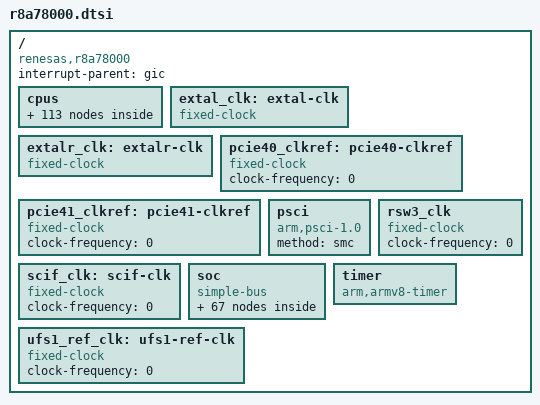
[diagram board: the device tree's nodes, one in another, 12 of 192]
// SPDX-License-Identifier: (GPL-2.0-only OR BSD-2-Clause)
/*
 * Device Tree Source for the R-Car X5H (R8A78000) SoC
 *
 * Copyright (C) 2025 Renesas Electronics Corp.
 */

#include <dt-bindings/clock/renesas,r8a78000-cpg.h>
#include <dt-bindings/power/renesas,r8a78000-mdlc.h>
#include <dt-bindings/interrupt-controller/arm-gic.h>

/ {
	compatible = "renesas,r8a78000";
	#address-cells = <2>;
	#size-cells = <2>;
	interrupt-parent = <&gic>;

	cpus {
		#address-cells = <2>;
		#size-cells = <0>;

		cpu-map {
			cluster0 {
				core0 {
					cpu = <&a720_0>;
				};
				core1 {
					cpu = <&a720_1>;
				};
				core2 {
					cpu = <&a720_2>;
				};
				core3 {
					cpu = <&a720_3>;
				};
			};

			cluster1 {
				core0 {
					cpu = <&a720_4>;
				};
				core1 {
					cpu = <&a720_5>;
				};
				core2 {
					cpu = <&a720_6>;
				};
				core3 {
					cpu = <&a720_7>;
				};
			};

			cluster2 {
				core0 {
					cpu = <&a720_8>;
				};
				core1 {
					cpu = <&a720_9>;
				};
				core2 {
					cpu = <&a720_10>;
				};
				core3 {
					cpu = <&a720_11>;
				};
			};

			cluster3 {
				core0 {
					cpu = <&a720_12>;
				};
				core1 {
					cpu = <&a720_13>;
				};
				core2 {
					cpu = <&a720_14>;
				};
				core3 {
					cpu = <&a720_15>;
				};
			};

			cluster4 {
				core0 {
					cpu = <&a720_16>;
				};
				core1 {
					cpu = <&a720_17>;
				};
				core2 {
					cpu = <&a720_18>;
				};
				core3 {
					cpu = <&a720_19>;
				};
			};

			cluster5 {
				core0 {
					cpu = <&a720_20>;
				};
				core1 {
					cpu = <&a720_21>;
				};
				core2 {
					cpu = <&a720_22>;
				};
				core3 {
					cpu = <&a720_23>;
				};
			};

			cluster6 {
				core0 {
					cpu = <&a720_24>;
				};
				core1 {
					cpu = <&a720_25>;
				};
				core2 {
					cpu = <&a720_26>;
				};
				core3 {
					cpu = <&a720_27>;
				};
			};

			cluster7 {
				core0 {
					cpu = <&a720_28>;
				};
				core1 {
					cpu = <&a720_29>;
				};
				core2 {
					cpu = <&a720_30>;
				};
				core3 {
					cpu = <&a720_31>;
				};
			};
		};

		a720_0: cpu@0 {
			compatible = "arm,cortex-a720ae";
			reg = <0x0 0x0>;
			device_type = "cpu";
			enable-method = "psci";
			next-level-cache = <&L2_CA720_0>;
		};

		a720_1: cpu@100 {
			compatible = "arm,cortex-a720ae";
			reg = <0x0 0x100>;
			device_type = "cpu";
			enable-method = "psci";
			next-level-cache = <&L2_CA720_1>;
		};

		a720_2: cpu@200 {
			compatible = "arm,cortex-a720ae";
			reg = <0x0 0x200>;
			device_type = "cpu";
			enable-method = "psci";
			next-level-cache = <&L2_CA720_2>;
		};

		a720_3: cpu@300 {
			compatible = "arm,cortex-a720ae";
			reg = <0x0 0x300>;
			device_type = "cpu";
			enable-method = "psci";
			next-level-cache = <&L2_CA720_3>;
		};

		a720_4: cpu@10000 {
			compatible = "arm,cortex-a720ae";
			reg = <0x0 0x10000>;
			device_type = "cpu";
			enable-method = "psci";
			next-level-cache = <&L2_CA720_4>;
		};

		a720_5: cpu@10100 {
			compatible = "arm,cortex-a720ae";
			reg = <0x0 0x10100>;
			device_type = "cpu";
			enable-method = "psci";
			next-level-cache = <&L2_CA720_5>;
		};

		a720_6: cpu@10200 {
			compatible = "arm,cortex-a720ae";
			reg = <0x0 0x10200>;
			device_type = "cpu";
			enable-method = "psci";
			next-level-cache = <&L2_CA720_6>;
		};

		a720_7: cpu@10300 {
			compatible = "arm,cortex-a720ae";
			reg = <0x0 0x10300>;
			device_type = "cpu";
			enable-method = "psci";
			next-level-cache = <&L2_CA720_7>;
		};

		a720_8: cpu@20000 {
			compatible = "arm,cortex-a720ae";
			reg = <0x0 0x20000>;
			device_type = "cpu";
			enable-method = "psci";
			next-level-cache = <&L2_CA720_8>;
		};

		a720_9: cpu@20100 {
			compatible = "arm,cortex-a720ae";
			reg = <0x0 0x20100>;
			device_type = "cpu";
			enable-method = "psci";
			next-level-cache = <&L2_CA720_9>;
		};

		a720_10: cpu@20200 {
			compatible = "arm,cortex-a720ae";
			reg = <0x0 0x20200>;
			device_type = "cpu";
			enable-method = "psci";
			next-level-cache = <&L2_CA720_10>;
		};

		a720_11: cpu@20300 {
			compatible = "arm,cortex-a720ae";
			reg = <0x0 0x20300>;
			device_type = "cpu";
			enable-method = "psci";
			next-level-cache = <&L2_CA720_11>;
		};

		a720_12: cpu@30000 {
			compatible = "arm,cortex-a720ae";
			reg = <0x0 0x30000>;
			device_type = "cpu";
			enable-method = "psci";
			next-level-cache = <&L2_CA720_12>;
		};

		a720_13: cpu@30100 {
			compatible = "arm,cortex-a720ae";
			reg = <0x0 0x30100>;
			device_type = "cpu";
			enable-method = "psci";
			next-level-cache = <&L2_CA720_13>;
		};

		a720_14: cpu@30200 {
			compatible = "arm,cortex-a720ae";
			reg = <0x0 0x30200>;
			device_type = "cpu";
			enable-method = "psci";
			next-level-cache = <&L2_CA720_14>;
		};

		a720_15: cpu@30300 {
			compatible = "arm,cortex-a720ae";
			reg = <0x0 0x30300>;
			device_type = "cpu";
			enable-method = "psci";
			next-level-cache = <&L2_CA720_15>;
		};

		a720_16: cpu@40000 {
			compatible = "arm,cortex-a720ae";
			reg = <0x0 0x40000>;
			device_type = "cpu";
			enable-method = "psci";
			next-level-cache = <&L2_CA720_16>;
		};

		a720_17: cpu@40100 {
			compatible = "arm,cortex-a720ae";
			reg = <0x0 0x40100>;
			device_type = "cpu";
			enable-method = "psci";
			next-level-cache = <&L2_CA720_17>;
		};

		a720_18: cpu@40200 {
			compatible = "arm,cortex-a720ae";
			reg = <0x0 0x40200>;
			device_type = "cpu";
			enable-method = "psci";
			next-level-cache = <&L2_CA720_18>;
		};

		a720_19: cpu@40300 {
			compatible = "arm,cortex-a720ae";
			reg = <0x0 0x40300>;
			device_type = "cpu";
			enable-method = "psci";
			next-level-cache = <&L2_CA720_19>;
		};

		a720_20: cpu@50000 {
			compatible = "arm,cortex-a720ae";
			reg = <0x0 0x50000>;
			device_type = "cpu";
			enable-method = "psci";
			next-level-cache = <&L2_CA720_20>;
		};

		a720_21: cpu@50100 {
			compatible = "arm,cortex-a720ae";
			reg = <0x0 0x50100>;
			device_type = "cpu";
			enable-method = "psci";
			next-level-cache = <&L2_CA720_21>;
		};

		a720_22: cpu@50200 {
			compatible = "arm,cortex-a720ae";
			reg = <0x0 0x50200>;
			device_type = "cpu";
			enable-method = "psci";
			next-level-cache = <&L2_CA720_22>;
		};

		a720_23: cpu@50300 {
			compatible = "arm,cortex-a720ae";
			reg = <0x0 0x50300>;
			device_type = "cpu";
			enable-method = "psci";
			next-level-cache = <&L2_CA720_23>;
		};

		a720_24: cpu@60000 {
			compatible = "arm,cortex-a720ae";
			reg = <0x0 0x60000>;
			device_type = "cpu";
			enable-method = "psci";
			next-level-cache = <&L2_CA720_24>;
		};

		a720_25: cpu@60100 {
			compatible = "arm,cortex-a720ae";
			reg = <0x0 0x60100>;
			device_type = "cpu";
			enable-method = "psci";
			next-level-cache = <&L2_CA720_25>;
		};

		a720_26: cpu@60200 {
			compatible = "arm,cortex-a720ae";
			reg = <0x0 0x60200>;
			device_type = "cpu";
			enable-method = "psci";
			next-level-cache = <&L2_CA720_26>;
		};

		a720_27: cpu@60300 {
			compatible = "arm,cortex-a720ae";
			reg = <0x0 0x60300>;
			device_type = "cpu";
			enable-method = "psci";
			next-level-cache = <&L2_CA720_27>;
		};

		a720_28: cpu@70000 {
			compatible = "arm,cortex-a720ae";
			reg = <0x0 0x70000>;
			device_type = "cpu";
			enable-method = "psci";
			next-level-cache = <&L2_CA720_28>;
		};

		a720_29: cpu@70100 {
			compatible = "arm,cortex-a720ae";
			reg = <0x0 0x70100>;
			device_type = "cpu";
			enable-method = "psci";
			next-level-cache = <&L2_CA720_29>;
		};

		a720_30: cpu@70200 {
			compatible = "arm,cortex-a720ae";
			reg = <0x0 0x70200>;
			device_type = "cpu";
			enable-method = "psci";
			next-level-cache = <&L2_CA720_30>;
		};

		a720_31: cpu@70300 {
			compatible = "arm,cortex-a720ae";
			reg = <0x0 0x70300>;
			device_type = "cpu";
			enable-method = "psci";
			next-level-cache = <&L2_CA720_31>;
		};

		L2_CA720_0: cache-controller-200 {
			compatible = "cache";
			cache-unified;
			cache-level = <2>;
			next-level-cache = <&L3_CA720_0>;
		};

		L2_CA720_1: cache-controller-201 {
			compatible = "cache";
			cache-unified;
			cache-level = <2>;
			next-level-cache = <&L3_CA720_0>;
		};

		L2_CA720_2: cache-controller-202 {
			compatible = "cache";
			cache-unified;
			cache-level = <2>;
			next-level-cache = <&L3_CA720_0>;
		};

		L2_CA720_3: cache-controller-203 {
			compatible = "cache";
			cache-unified;
			cache-level = <2>;
			next-level-cache = <&L3_CA720_0>;
		};

		L2_CA720_4: cache-controller-204 {
			compatible = "cache";
			cache-unified;
			cache-level = <2>;
			next-level-cache = <&L3_CA720_1>;
		};

		L2_CA720_5: cache-controller-205 {
			compatible = "cache";
			cache-unified;
			cache-level = <2>;
			next-level-cache = <&L3_CA720_1>;
		};

		L2_CA720_6: cache-controller-206 {
			compatible = "cache";
			cache-unified;
			cache-level = <2>;
			next-level-cache = <&L3_CA720_1>;
		};

		L2_CA720_7: cache-controller-207 {
			compatible = "cache";
			cache-unified;
			cache-level = <2>;
			next-level-cache = <&L3_CA720_1>;
		};

		L2_CA720_8: cache-controller-208 {
			compatible = "cache";
			cache-unified;
			cache-level = <2>;
			next-level-cache = <&L3_CA720_2>;
		};

		L2_CA720_9: cache-controller-209 {
			compatible = "cache";
			cache-unified;
			cache-level = <2>;
			next-level-cache = <&L3_CA720_2>;
		};

		L2_CA720_10: cache-controller-210 {
			compatible = "cache";
			cache-unified;
			cache-level = <2>;
			next-level-cache = <&L3_CA720_2>;
		};

		L2_CA720_11: cache-controller-211 {
			compatible = "cache";
			cache-unified;
			cache-level = <2>;
			next-level-cache = <&L3_CA720_2>;
		};

		L2_CA720_12: cache-controller-212 {
			compatible = "cache";
			cache-unified;
			cache-level = <2>;
			next-level-cache = <&L3_CA720_3>;
		};

		L2_CA720_13: cache-controller-213 {
			compatible = "cache";
			cache-unified;
			cache-level = <2>;
			next-level-cache = <&L3_CA720_3>;
		};

		L2_CA720_14: cache-controller-214 {
			compatible = "cache";
			cache-unified;
			cache-level = <2>;
			next-level-cache = <&L3_CA720_3>;
		};

		L2_CA720_15: cache-controller-215 {
			compatible = "cache";
			cache-unified;
			cache-level = <2>;
			next-level-cache = <&L3_CA720_3>;
		};

		L2_CA720_16: cache-controller-216 {
			compatible = "cache";
			cache-unified;
			cache-level = <2>;
			next-level-cache = <&L3_CA720_4>;
		};

		L2_CA720_17: cache-controller-217 {
			compatible = "cache";
			cache-unified;
			cache-level = <2>;
			next-level-cache = <&L3_CA720_4>;
		};

		L2_CA720_18: cache-controller-218 {
			compatible = "cache";
			cache-unified;
			cache-level = <2>;
			next-level-cache = <&L3_CA720_4>;
		};

		L2_CA720_19: cache-controller-219 {
			compatible = "cache";
			cache-unified;
			cache-level = <2>;
			next-level-cache = <&L3_CA720_4>;
		};

		L2_CA720_20: cache-controller-220 {
			compatible = "cache";
			cache-unified;
			cache-level = <2>;
			next-level-cache = <&L3_CA720_5>;
		};

		L2_CA720_21: cache-controller-221 {
			compatible = "cache";
			cache-unified;
			cache-level = <2>;
			next-level-cache = <&L3_CA720_5>;
		};

		L2_CA720_22: cache-controller-222 {
			compatible = "cache";
			cache-unified;
			cache-level = <2>;
			next-level-cache = <&L3_CA720_5>;
		};

		L2_CA720_23: cache-controller-223 {
			compatible = "cache";
			cache-unified;
			cache-level = <2>;
			next-level-cache = <&L3_CA720_5>;
		};

		L2_CA720_24: cache-controller-224 {
			compatible = "cache";
			cache-unified;
			cache-level = <2>;
			next-level-cache = <&L3_CA720_6>;
		};

		L2_CA720_25: cache-controller-225 {
			compatible = "cache";
			cache-unified;
			cache-level = <2>;
			next-level-cache = <&L3_CA720_6>;
		};

		L2_CA720_26: cache-controller-226 {
			compatible = "cache";
			cache-unified;
			cache-level = <2>;
			next-level-cache = <&L3_CA720_6>;
		};

		L2_CA720_27: cache-controller-227 {
			compatible = "cache";
			cache-unified;
			cache-level = <2>;
			next-level-cache = <&L3_CA720_6>;
		};

		L2_CA720_28: cache-controller-228 {
			compatible = "cache";
			cache-unified;
			cache-level = <2>;
			next-level-cache = <&L3_CA720_7>;
		};

		L2_CA720_29: cache-controller-229 {
			compatible = "cache";
			cache-unified;
			cache-level = <2>;
			next-level-cache = <&L3_CA720_7>;
		};

		L2_CA720_30: cache-controller-230 {
			compatible = "cache";
			cache-unified;
			cache-level = <2>;
			next-level-cache = <&L3_CA720_7>;
		};

		L2_CA720_31: cache-controller-231 {
			compatible = "cache";
			cache-unified;
			cache-level = <2>;
			next-level-cache = <&L3_CA720_7>;
		};

		L3_CA720_0: cache-controller-30 {
			compatible = "cache";
			cache-unified;
			cache-level = <3>;
		};

		L3_CA720_1: cache-controller-31 {
			compatible = "cache";
			cache-unified;
			cache-level = <3>;
		};

		L3_CA720_2: cache-controller-32 {
			compatible = "cache";
			cache-unified;
			cache-level = <3>;
		};

		L3_CA720_3: cache-controller-33 {
			compatible = "cache";
			cache-unified;
			cache-level = <3>;
		};

		L3_CA720_4: cache-controller-34 {
			compatible = "cache";
			cache-unified;
			cache-level = <3>;
		};

		L3_CA720_5: cache-controller-35 {
			compatible = "cache";
			cache-unified;
			cache-level = <3>;
		};

		L3_CA720_6: cache-controller-36 {
			compatible = "cache";
			cache-unified;
			cache-level = <3>;
		};

		L3_CA720_7: cache-controller-37 {
			compatible = "cache";
			cache-unified;
			cache-level = <3>;
		};
	};

	extal_clk: extal-clk {
		compatible = "fixed-clock";
		#clock-cells = <0>;
		/* clock-frequency must be set on board */
	};

	extalr_clk: extalr-clk {
		compatible = "fixed-clock";
		#clock-cells = <0>;
		/* clock-frequency must be set on board */
	};

	pcie40_clkref: pcie40-clkref {
		compatible = "fixed-clock";
		#clock-cells = <0>;
		/* This value must be overridden by the board */
		clock-frequency = <0>;
	};

	pcie41_clkref: pcie41-clkref {
		compatible = "fixed-clock";
		#clock-cells = <0>;
		/* This value must be overridden by the board */
		clock-frequency = <0>;
	};

	psci {
		compatible = "arm,psci-1.0";
		method = "smc";
	};

	rsw3_clk: rsw3_clk {
		compatible = "fixed-clock";
		#clock-cells = <0>;
		clock-frequency = <0>;
	};

	/* External SCIF clock - to be overridden by boards that provide it */
	scif_clk: scif-clk {
		compatible = "fixed-clock";
		#clock-cells = <0>;
		clock-frequency = <0>; /* optional */
	};

	soc: soc {
		compatible = "simple-bus";
		#address-cells = <2>;
		#size-cells = <2>;
		ranges;

		mfis: system-controller@189e0000 {
			compatible = "renesas,r8a78000-mfis";
			reg = <0 0x189e0000 0 0x1000>, <0 0x18800000 0 0x40000>;
			reg-names = "common", "mboxes";
			interrupts = <GIC_SPI 101 IRQ_TYPE_LEVEL_HIGH>, <GIC_SPI 102 IRQ_TYPE_LEVEL_HIGH>,
				     <GIC_SPI 103 IRQ_TYPE_LEVEL_HIGH>, <GIC_SPI 104 IRQ_TYPE_LEVEL_HIGH>,
				     <GIC_SPI 105 IRQ_TYPE_LEVEL_HIGH>, <GIC_SPI 106 IRQ_TYPE_LEVEL_HIGH>,
				     <GIC_SPI 107 IRQ_TYPE_LEVEL_HIGH>, <GIC_SPI 108 IRQ_TYPE_LEVEL_HIGH>,
				     <GIC_SPI 109 IRQ_TYPE_LEVEL_HIGH>, <GIC_SPI 110 IRQ_TYPE_LEVEL_HIGH>,
				     <GIC_SPI 111 IRQ_TYPE_LEVEL_HIGH>, <GIC_SPI 112 IRQ_TYPE_LEVEL_HIGH>,
				     <GIC_SPI 113 IRQ_TYPE_LEVEL_HIGH>, <GIC_SPI 114 IRQ_TYPE_LEVEL_HIGH>,
				     <GIC_SPI 115 IRQ_TYPE_LEVEL_HIGH>, <GIC_SPI 116 IRQ_TYPE_LEVEL_HIGH>,
				     <GIC_SPI 117 IRQ_TYPE_LEVEL_HIGH>, <GIC_SPI 118 IRQ_TYPE_LEVEL_HIGH>,
				     <GIC_SPI 119 IRQ_TYPE_LEVEL_HIGH>, <GIC_SPI 120 IRQ_TYPE_LEVEL_HIGH>,
				     <GIC_SPI 121 IRQ_TYPE_LEVEL_HIGH>, <GIC_SPI 122 IRQ_TYPE_LEVEL_HIGH>,
				     <GIC_SPI 123 IRQ_TYPE_LEVEL_HIGH>, <GIC_SPI 124 IRQ_TYPE_LEVEL_HIGH>,
				     <GIC_SPI 125 IRQ_TYPE_LEVEL_HIGH>, <GIC_SPI 126 IRQ_TYPE_LEVEL_HIGH>,
				     <GIC_SPI 127 IRQ_TYPE_LEVEL_HIGH>, <GIC_SPI 128 IRQ_TYPE_LEVEL_HIGH>,
				     <GIC_SPI 129 IRQ_TYPE_LEVEL_HIGH>, <GIC_SPI 130 IRQ_TYPE_LEVEL_HIGH>,
				     <GIC_SPI 131 IRQ_TYPE_LEVEL_HIGH>, <GIC_SPI 132 IRQ_TYPE_LEVEL_HIGH>,
				     <GIC_SPI 133 IRQ_TYPE_LEVEL_HIGH>, <GIC_SPI 134 IRQ_TYPE_LEVEL_HIGH>,
				     <GIC_SPI 135 IRQ_TYPE_LEVEL_HIGH>, <GIC_SPI 136 IRQ_TYPE_LEVEL_HIGH>,
				     <GIC_SPI 137 IRQ_TYPE_LEVEL_HIGH>, <GIC_SPI 138 IRQ_TYPE_LEVEL_HIGH>,
				     <GIC_SPI 139 IRQ_TYPE_LEVEL_HIGH>, <GIC_SPI 140 IRQ_TYPE_LEVEL_HIGH>,
				     <GIC_SPI 141 IRQ_TYPE_LEVEL_HIGH>, <GIC_SPI 142 IRQ_TYPE_LEVEL_HIGH>,
				     <GIC_SPI 143 IRQ_TYPE_LEVEL_HIGH>, <GIC_SPI 144 IRQ_TYPE_LEVEL_HIGH>,
				     <GIC_SPI 145 IRQ_TYPE_LEVEL_HIGH>, <GIC_SPI 146 IRQ_TYPE_LEVEL_HIGH>,
				     <GIC_SPI 147 IRQ_TYPE_LEVEL_HIGH>, <GIC_SPI 148 IRQ_TYPE_LEVEL_HIGH>,
				     <GIC_SPI 149 IRQ_TYPE_LEVEL_HIGH>, <GIC_SPI 150 IRQ_TYPE_LEVEL_HIGH>,
				     <GIC_SPI 151 IRQ_TYPE_LEVEL_HIGH>, <GIC_SPI 152 IRQ_TYPE_LEVEL_HIGH>,
				     <GIC_SPI 153 IRQ_TYPE_LEVEL_HIGH>, <GIC_SPI 154 IRQ_TYPE_LEVEL_HIGH>,
				     <GIC_SPI 155 IRQ_TYPE_LEVEL_HIGH>, <GIC_SPI 156 IRQ_TYPE_LEVEL_HIGH>,
				     <GIC_SPI 157 IRQ_TYPE_LEVEL_HIGH>, <GIC_SPI 158 IRQ_TYPE_LEVEL_HIGH>,
				     <GIC_SPI 159 IRQ_TYPE_LEVEL_HIGH>, <GIC_SPI 160 IRQ_TYPE_LEVEL_HIGH>,
				     <GIC_SPI 161 IRQ_TYPE_LEVEL_HIGH>, <GIC_SPI 162 IRQ_TYPE_LEVEL_HIGH>,
				     <GIC_SPI 163 IRQ_TYPE_LEVEL_HIGH>, <GIC_SPI 164 IRQ_TYPE_LEVEL_HIGH>,
				     <GIC_SPI 165 IRQ_TYPE_LEVEL_HIGH>, <GIC_SPI 166 IRQ_TYPE_LEVEL_HIGH>,
				     <GIC_SPI 167 IRQ_TYPE_LEVEL_HIGH>, <GIC_SPI 168 IRQ_TYPE_LEVEL_HIGH>,
				     <GIC_SPI 169 IRQ_TYPE_LEVEL_HIGH>, <GIC_SPI 170 IRQ_TYPE_LEVEL_HIGH>,
				     <GIC_SPI 171 IRQ_TYPE_LEVEL_HIGH>, <GIC_SPI 172 IRQ_TYPE_LEVEL_HIGH>,
				     <GIC_SPI 173 IRQ_TYPE_LEVEL_HIGH>, <GIC_SPI 174 IRQ_TYPE_LEVEL_HIGH>,
				     <GIC_SPI 175 IRQ_TYPE_LEVEL_HIGH>, <GIC_SPI 176 IRQ_TYPE_LEVEL_HIGH>,
				     <GIC_SPI 177 IRQ_TYPE_LEVEL_HIGH>, <GIC_SPI 178 IRQ_TYPE_LEVEL_HIGH>,
				     <GIC_SPI 179 IRQ_TYPE_LEVEL_HIGH>, <GIC_SPI 180 IRQ_TYPE_LEVEL_HIGH>,
				     <GIC_SPI 181 IRQ_TYPE_LEVEL_HIGH>, <GIC_SPI 182 IRQ_TYPE_LEVEL_HIGH>,
				     <GIC_SPI 183 IRQ_TYPE_LEVEL_HIGH>, <GIC_SPI 184 IRQ_TYPE_LEVEL_HIGH>,
				     <GIC_SPI 185 IRQ_TYPE_LEVEL_HIGH>, <GIC_SPI 186 IRQ_TYPE_LEVEL_HIGH>,
				     <GIC_SPI 187 IRQ_TYPE_LEVEL_HIGH>, <GIC_SPI 188 IRQ_TYPE_LEVEL_HIGH>,
				     <GIC_SPI 189 IRQ_TYPE_LEVEL_HIGH>, <GIC_SPI 190 IRQ_TYPE_LEVEL_HIGH>,
				     <GIC_SPI 191 IRQ_TYPE_LEVEL_HIGH>, <GIC_SPI 192 IRQ_TYPE_LEVEL_HIGH>,
				     <GIC_SPI 193 IRQ_TYPE_LEVEL_HIGH>, <GIC_SPI 194 IRQ_TYPE_LEVEL_HIGH>,
				     <GIC_SPI 195 IRQ_TYPE_LEVEL_HIGH>, <GIC_SPI 196 IRQ_TYPE_LEVEL_HIGH>,
				     <GIC_SPI 197 IRQ_TYPE_LEVEL_HIGH>, <GIC_SPI 198 IRQ_TYPE_LEVEL_HIGH>,
				     <GIC_SPI 199 IRQ_TYPE_LEVEL_HIGH>, <GIC_SPI 200 IRQ_TYPE_LEVEL_HIGH>,
				     <GIC_SPI 201 IRQ_TYPE_LEVEL_HIGH>, <GIC_SPI 202 IRQ_TYPE_LEVEL_HIGH>,
				     <GIC_SPI 203 IRQ_TYPE_LEVEL_HIGH>, <GIC_SPI 204 IRQ_TYPE_LEVEL_HIGH>,
				     <GIC_SPI 205 IRQ_TYPE_LEVEL_HIGH>, <GIC_SPI 206 IRQ_TYPE_LEVEL_HIGH>,
				     <GIC_SPI 207 IRQ_TYPE_LEVEL_HIGH>, <GIC_SPI 208 IRQ_TYPE_LEVEL_HIGH>,
				     <GIC_SPI 209 IRQ_TYPE_LEVEL_HIGH>, <GIC_SPI 210 IRQ_TYPE_LEVEL_HIGH>,
				     <GIC_SPI 211 IRQ_TYPE_LEVEL_HIGH>, <GIC_SPI 212 IRQ_TYPE_LEVEL_HIGH>,
				     <GIC_SPI 213 IRQ_TYPE_LEVEL_HIGH>, <GIC_SPI 214 IRQ_TYPE_LEVEL_HIGH>,
				     <GIC_SPI 215 IRQ_TYPE_LEVEL_HIGH>, <GIC_SPI 216 IRQ_TYPE_LEVEL_HIGH>,
				     <GIC_SPI 217 IRQ_TYPE_LEVEL_HIGH>, <GIC_SPI 218 IRQ_TYPE_LEVEL_HIGH>,
				     <GIC_SPI 219 IRQ_TYPE_LEVEL_HIGH>, <GIC_SPI 220 IRQ_TYPE_LEVEL_HIGH>,
				     <GIC_SPI 221 IRQ_TYPE_LEVEL_HIGH>, <GIC_SPI 222 IRQ_TYPE_LEVEL_HIGH>,
				     <GIC_SPI 223 IRQ_TYPE_LEVEL_HIGH>, <GIC_SPI 224 IRQ_TYPE_LEVEL_HIGH>,
				     <GIC_SPI 225 IRQ_TYPE_LEVEL_HIGH>, <GIC_SPI 226 IRQ_TYPE_LEVEL_HIGH>,
				     <GIC_SPI 227 IRQ_TYPE_LEVEL_HIGH>, <GIC_SPI 228 IRQ_TYPE_LEVEL_HIGH>;
			interrupt-names = "ch0i", "ch0e", "ch1i", "ch1e", "ch2i", "ch2e", "ch3i", "ch3e",
					  "ch4i", "ch4e", "ch5i", "ch5e", "ch6i", "ch6e", "ch7i", "ch7e",
					  "ch8i", "ch8e", "ch9i", "ch9e", "ch10i", "ch10e", "ch11i", "ch11e",
					  "ch12i", "ch12e", "ch13i", "ch13e", "ch14i", "ch14e", "ch15i", "ch15e",
					  "ch16i", "ch16e", "ch17i", "ch17e", "ch18i", "ch18e", "ch19i", "ch19e",
					  "ch20i", "ch20e", "ch21i", "ch21e", "ch22i", "ch22e", "ch23i", "ch23e",
					  "ch24i", "ch24e", "ch25i", "ch25e", "ch26i", "ch26e", "ch27i", "ch27e",
					  "ch28i", "ch28e", "ch29i", "ch29e", "ch30i", "ch30e", "ch31i", "ch31e",
					  "ch32i", "ch32e", "ch33i", "ch33e", "ch34i", "ch34e", "ch35i", "ch35e",
					  "ch36i", "ch36e", "ch37i", "ch37e", "ch38i", "ch38e", "ch39i", "ch39e",
					  "ch40i", "ch40e", "ch41i", "ch41e", "ch42i", "ch42e", "ch43i", "ch43e",
					  "ch44i", "ch44e", "ch45i", "ch45e", "ch46i", "ch46e", "ch47i", "ch47e",
					  "ch48i", "ch48e", "ch49i", "ch49e", "ch50i", "ch50e", "ch51i", "ch51e",
					  "ch52i", "ch52e", "ch53i", "ch53e", "ch54i", "ch54e", "ch55i", "ch55e",
					  "ch56i", "ch56e", "ch57i", "ch57e", "ch58i", "ch58e", "ch59i", "ch59e",
					  "ch60i", "ch60e", "ch61i", "ch61e", "ch62i", "ch62e", "ch63i", "ch63e";
			#mbox-cells = <2>;
			#hwlock-cells = <1>;
			status = "disabled";
		};

		mfis_scp: system-controller@189e1000 {
			compatible = "renesas,r8a78000-mfis-scp";
			reg = <0 0x189e1000 0 0x1000>, <0 0x18840000 0 0x2c000>;
			reg-names = "common", "mboxes";
			interrupts = <GIC_ESPI 296 IRQ_TYPE_LEVEL_HIGH>, <GIC_ESPI 297 IRQ_TYPE_LEVEL_HIGH>,
				     <GIC_ESPI 298 IRQ_TYPE_LEVEL_HIGH>, <GIC_ESPI 299 IRQ_TYPE_LEVEL_HIGH>,
				     <GIC_ESPI 300 IRQ_TYPE_LEVEL_HIGH>, <GIC_ESPI 301 IRQ_TYPE_LEVEL_HIGH>,
				     <GIC_ESPI 302 IRQ_TYPE_LEVEL_HIGH>, <GIC_ESPI 303 IRQ_TYPE_LEVEL_HIGH>,
				     <GIC_ESPI 304 IRQ_TYPE_LEVEL_HIGH>, <GIC_ESPI 305 IRQ_TYPE_LEVEL_HIGH>,
				     <GIC_ESPI 306 IRQ_TYPE_LEVEL_HIGH>, <GIC_ESPI 307 IRQ_TYPE_LEVEL_HIGH>,
				     <GIC_ESPI 308 IRQ_TYPE_LEVEL_HIGH>, <GIC_ESPI 309 IRQ_TYPE_LEVEL_HIGH>,
				     <GIC_ESPI 310 IRQ_TYPE_LEVEL_HIGH>, <GIC_ESPI 311 IRQ_TYPE_LEVEL_HIGH>,
				     <GIC_ESPI 312 IRQ_TYPE_LEVEL_HIGH>, <GIC_ESPI 313 IRQ_TYPE_LEVEL_HIGH>,
				     <GIC_ESPI 314 IRQ_TYPE_LEVEL_HIGH>, <GIC_ESPI 315 IRQ_TYPE_LEVEL_HIGH>,
				     <GIC_ESPI 316 IRQ_TYPE_LEVEL_HIGH>, <GIC_ESPI 317 IRQ_TYPE_LEVEL_HIGH>,
				     <GIC_ESPI 318 IRQ_TYPE_LEVEL_HIGH>, <GIC_ESPI 319 IRQ_TYPE_LEVEL_HIGH>,
				     <GIC_ESPI 320 IRQ_TYPE_LEVEL_HIGH>, <GIC_ESPI 321 IRQ_TYPE_LEVEL_HIGH>,
				     <GIC_ESPI 322 IRQ_TYPE_LEVEL_HIGH>, <GIC_ESPI 323 IRQ_TYPE_LEVEL_HIGH>,
				     <GIC_ESPI 324 IRQ_TYPE_LEVEL_HIGH>, <GIC_ESPI 325 IRQ_TYPE_LEVEL_HIGH>,
				     <GIC_ESPI 326 IRQ_TYPE_LEVEL_HIGH>, <GIC_ESPI 327 IRQ_TYPE_LEVEL_HIGH>;
			/* SCP uses I side IRQ only */
			interrupt-names = "ch0i", "ch1i", "ch2i", "ch3i", "ch4i", "ch5i", "ch6i", "ch7i",
					  "ch8i", "ch9i", "ch10i", "ch11i", "ch12i", "ch13i", "ch14i", "ch15i",
					  "ch16i", "ch17i", "ch18i", "ch19i", "ch20i", "ch21i", "ch22i", "ch23i",
					  "ch24i", "ch25i", "ch26i", "ch27i", "ch28i", "ch29i", "ch30i", "ch31i";
			#mbox-cells = <2>;
			#hwlock-cells = <1>;
			status = "disabled";
		};

		/* Application Processors manage View-1 of a GIC-720AE */
		gic: interrupt-controller@39000000 {
			compatible = "arm,gic-v3";
			#interrupt-cells = <3>;
			#address-cells = <0>;
			interrupt-controller;
			#redistributor-regions = <32>;
			reg = <0x0 0x39000000 0x0 0x10000>,
			      <0x0 0x39080000 0x0 0x40000>,
			      <0x0 0x390c0000 0x0 0x40000>,
			      <0x0 0x39100000 0x0 0x40000>,
			      <0x0 0x39140000 0x0 0x40000>,
			      <0x0 0x39180000 0x0 0x40000>,
			      <0x0 0x391c0000 0x0 0x40000>,
			      <0x0 0x39200000 0x0 0x40000>,
			      <0x0 0x39240000 0x0 0x40000>,
			      <0x0 0x39280000 0x0 0x40000>,
			      <0x0 0x392c0000 0x0 0x40000>,
			      <0x0 0x39300000 0x0 0x40000>,
			      <0x0 0x39340000 0x0 0x40000>,
			      <0x0 0x39380000 0x0 0x40000>,
			      <0x0 0x393c0000 0x0 0x40000>,
			      <0x0 0x39400000 0x0 0x40000>,
			      <0x0 0x39440000 0x0 0x40000>,
			      <0x0 0x39480000 0x0 0x40000>,
			      <0x0 0x394c0000 0x0 0x40000>,
			      <0x0 0x39500000 0x0 0x40000>,
			      <0x0 0x39540000 0x0 0x40000>,
			      <0x0 0x39580000 0x0 0x40000>,
			      <0x0 0x395c0000 0x0 0x40000>,
			      <0x0 0x39600000 0x0 0x40000>,
			      <0x0 0x39640000 0x0 0x40000>,
			      <0x0 0x39680000 0x0 0x40000>,
			      <0x0 0x396c0000 0x0 0x40000>,
			      <0x0 0x39700000 0x0 0x40000>,
			      <0x0 0x39740000 0x0 0x40000>,
			      <0x0 0x39780000 0x0 0x40000>,
			      <0x0 0x397c0000 0x0 0x40000>,
			      <0x0 0x39800000 0x0 0x40000>,
			      <0x0 0x39840000 0x0 0x40000>;
			interrupts = <GIC_PPI 9 IRQ_TYPE_LEVEL_HIGH>;
		};

		pfc: pinctrl@c1080000 {
			compatible = "renesas,pfc-r8a78000";
			reg = <0 0xc1080000 0 0x104>, <0 0xc1080800 0 0x104>,
			      <0 0xc1081000 0 0x104>, <0 0xc0800000 0 0x104>,
			      <0 0xc0800800 0 0x104>, <0 0xc0400000 0 0x104>,
			      <0 0xc0400800 0 0x104>, <0 0xc0401000 0 0x104>,
			      <0 0xc0401800 0 0x104>, <0 0xc9b00000 0 0x104>,
			      <0 0xc9b00800 0 0x104>;
			bootph-all;
		};

		gpio0: gpio@c1080110 {
			compatible = "renesas,gpio-r8a78000",
				     "renesas,rcar-gen5-gpio";
			reg = <0 0xc1080110 0 0xc0>;
			interrupts = <GIC_SPI 0 IRQ_TYPE_LEVEL_HIGH>;
			clocks = <&scmi_clk 811>; /* R8A78000_SCMI_CLOCK_MDLC_GPIODM0 */
			power-domains = <&scmi_devpd 0>; /* FIXME: Should be PD_APL, but SDK SCP exposes no PD_APL */
			resets = <&scmi_reset 811>; /* R8A78000_SCMI_RESET_GPIODM0 */
			#gpio-cells = <2>;
			gpio-controller;
			gpio-ranges = <&pfc 0 0 28>;
			#interrupt-cells = <2>;
			interrupt-controller;
		};

		gpio1: gpio@c1080910 {
			compatible = "renesas,gpio-r8a78000",
				     "renesas,rcar-gen5-gpio";
			reg = <0 0xc1080910 0 0xc0>;
			interrupts = <GIC_SPI 4 IRQ_TYPE_LEVEL_HIGH>;
			clocks = <&scmi_clk 811>; /* R8A78000_SCMI_CLOCK_MDLC_GPIODM0 */
			power-domains = <&scmi_devpd 0>; /* FIXME: Should be PD_APL, but SDK SCP exposes no PD_APL */
			resets = <&scmi_reset 811>; /* R8A78000_SCMI_RESET_GPIODM0 */
			#gpio-cells = <2>;
			gpio-controller;
			gpio-ranges = <&pfc 0 32 22>;
			#interrupt-cells = <2>;
			interrupt-controller;
		};

		gpio2: gpio@c1081110 {
			compatible = "renesas,gpio-r8a78000",
				     "renesas,rcar-gen5-gpio";
			reg = <0 0xc1081110 0 0xc0>;
			interrupts = <GIC_SPI 8 IRQ_TYPE_LEVEL_HIGH>;
			clocks = <&scmi_clk 811>; /* R8A78000_SCMI_CLOCK_MDLC_GPIODM0 */
			power-domains = <&scmi_devpd 0>; /* FIXME: Should be PD_APL, but SDK SCP exposes no PD_APL */
			resets = <&scmi_reset 811>; /* R8A78000_SCMI_RESET_GPIODM0 */
			#gpio-cells = <2>;
			gpio-controller;
			gpio-ranges = <&pfc 0 64 29>;
			#interrupt-cells = <2>;
			interrupt-controller;
		};

		gpio3: gpio@c0800110 {
			compatible = "renesas,gpio-r8a78000",
				     "renesas,rcar-gen5-gpio";
			reg = <0 0xc0800110 0 0xc0>;
			interrupts = <GIC_SPI 12 IRQ_TYPE_LEVEL_HIGH>;
			clocks = <&scmi_clk 193>; /* R8A78000_SCMI_CLOCK_MDLC_PERE_GPIODM0 */
			power-domains = <&scmi_devpd 0>; /* FIXME: Should be PD_APL, but SDK SCP exposes no PD_APL */
			resets = <&scmi_reset 193>; /* R8A78000_SCMI_RESET_PERE_GPIODM0 */
			#gpio-cells = <2>;
			gpio-controller;
			gpio-ranges = <&pfc 0 96 17>;
			#interrupt-cells = <2>;
			interrupt-controller;
		};

		gpio4: gpio@c0800910 {
			compatible = "renesas,gpio-r8a78000",
				     "renesas,rcar-gen5-gpio";
			reg = <0 0xc0800910 0 0xc0>;
			interrupts = <GIC_SPI 16 IRQ_TYPE_LEVEL_HIGH>;
			clocks = <&scmi_clk 193>; /* R8A78000_SCMI_CLOCK_MDLC_PERE_GPIODM0 */
			power-domains = <&scmi_devpd 0>; /* FIXME: Should be PD_APL, but SDK SCP exposes no PD_APL */
			resets = <&scmi_reset 193>; /* R8A78000_SCMI_RESET_PERE_GPIODM0 */
			#gpio-cells = <2>;
			gpio-controller;
			gpio-ranges = <&pfc 0 128 16>;
			#interrupt-cells = <2>;
			interrupt-controller;
		};

		gpio5: gpio@c0400110 {
			compatible = "renesas,gpio-r8a78000",
				     "renesas,rcar-gen5-gpio";
			reg = <0 0xc0400110 0 0xc0>;
			interrupts = <GIC_SPI 20 IRQ_TYPE_LEVEL_HIGH>;
			clocks = <&scmi_clk 201>; /* R8A78000_SCMI_CLOCK_MDLC_PERW_GPIODM0 */
			power-domains = <&scmi_devpd 0>; /* FIXME: Should be PD_APL, but SDK SCP exposes no PD_APL */
			resets = <&scmi_reset 201>; /* R8A78000_SCMI_RESET_PERW_GPIODM0 */
			#gpio-cells = <2>;
			gpio-controller;
			gpio-ranges = <&pfc 0 160 23>;
			#interrupt-cells = <2>;
			interrupt-controller;
		};

		gpio6: gpio@c0400910 {
			compatible = "renesas,gpio-r8a78000",
				     "renesas,rcar-gen5-gpio";
			reg = <0 0xc0400910 0 0xc0>;
			interrupts = <GIC_SPI 24 IRQ_TYPE_LEVEL_HIGH>;
			clocks = <&scmi_clk 201>; /* R8A78000_SCMI_CLOCK_MDLC_PERW_GPIODM0 */
			power-domains = <&scmi_devpd 0>; /* FIXME: Should be PD_APL, but SDK SCP exposes no PD_APL */
			resets = <&scmi_reset 201>; /* R8A78000_SCMI_RESET_PERW_GPIODM0 */
			#gpio-cells = <2>;
			gpio-controller;
			gpio-ranges = <&pfc 0 192 31>;
			#interrupt-cells = <2>;
			interrupt-controller;
		};

		gpio7: gpio@c0401110 {
			compatible = "renesas,gpio-r8a78000",
				     "renesas,rcar-gen5-gpio";
			reg = <0 0xc0401110 0 0xc0>;
			interrupts = <GIC_SPI 28 IRQ_TYPE_LEVEL_HIGH>;
			clocks = <&scmi_clk 201>; /* R8A78000_SCMI_CLOCK_MDLC_PERW_GPIODM0 */
			power-domains = <&scmi_devpd 0>; /* FIXME: Should be PD_APL, but SDK SCP exposes no PD_APL */
			resets = <&scmi_reset 201>; /* R8A78000_SCMI_RESET_PERW_GPIODM0 */
			#gpio-cells = <2>;
			gpio-controller;
			gpio-ranges = <&pfc 0 224 31>;
			#interrupt-cells = <2>;
			interrupt-controller;
		};

		gpio8: gpio@c0401910 {
			compatible = "renesas,gpio-r8a78000",
				     "renesas,rcar-gen5-gpio";
			reg = <0 0xc0401910 0 0xc0>;
			interrupts = <GIC_SPI 32 IRQ_TYPE_LEVEL_HIGH>;
			clocks = <&scmi_clk 201>; /* R8A78000_SCMI_CLOCK_MDLC_PERW_GPIODM0 */
			power-domains = <&scmi_devpd 0>; /* FIXME: Should be PD_APL, but SDK SCP exposes no PD_APL */
			resets = <&scmi_reset 201>; /* R8A78000_SCMI_RESET_PERW_GPIODM0 */
			#gpio-cells = <2>;
			gpio-controller;
			gpio-ranges = <&pfc 0 256 32>;
			gpio-reserved-ranges = <16 10>;
			#interrupt-cells = <2>;
			interrupt-controller;
		};

		gpio9: gpio@c9b00110 {
			compatible = "renesas,gpio-r8a78000",
				     "renesas,rcar-gen5-gpio";
			reg = <0 0xc9b00110 0 0xc0>;
			interrupts = <GIC_SPI 36 IRQ_TYPE_LEVEL_HIGH>;
			clocks = <&scmi_clk 332>; /* R8A78000_SCMI_CLOCK_MDLC_HSCN_GPIODM0 */
			power-domains = <&scmi_devpd 0>; /* FIXME: Should be PD_APL, but SDK SCP exposes no PD_APL */
			resets = <&scmi_reset 332>; /* R8A78000_SCMI_RESET_HSCN_GPIODM0 */
			#gpio-cells = <2>;
			gpio-controller;
			gpio-ranges = <&pfc 0 288 17>;
			#interrupt-cells = <2>;
			interrupt-controller;
		};

		gpio10: gpio@c9b00910 {
			compatible = "renesas,gpio-r8a78000",
				     "renesas,rcar-gen5-gpio";
			reg = <0 0xc9b00910 0 0xc0>;
			interrupts = <GIC_SPI 40 IRQ_TYPE_LEVEL_HIGH>;
			clocks = <&scmi_clk 332>; /* R8A78000_SCMI_CLOCK_MDLC_HSCN_GPIODM0 */
			power-domains = <&scmi_devpd 0>; /* FIXME: Should be PD_APL, but SDK SCP exposes no PD_APL */
			resets = <&scmi_reset 332>; /* R8A78000_SCMI_RESET_HSCN_GPIODM0 */
			#gpio-cells = <2>;
			gpio-controller;
			gpio-ranges = <&pfc 0 320 14>;
			#interrupt-cells = <2>;
			interrupt-controller;
		};

		scif0: serial@c0700000 {
			compatible = "renesas,scif-r8a78000",
				     "renesas,rcar-gen5-scif", "renesas,scif";
			reg = <0 0xc0700000 0 0x40>;
			interrupts = <GIC_ESPI 10 IRQ_TYPE_LEVEL_HIGH>;
			clocks = <&cpg R8A78000_CPG_SGASYNCD16_PERW_BUS>,
				 <&cpg R8A78000_CPG_SGASYNCD4_PERW_BUS>,
				 <&scif_clk>;
			clock-names = "fck", "brg_int", "scif_clk";
			power-domains = <&mdlc_perw R8A78000_MDLC_PD_APL 0x40>;
			resets = <&mdlc_perw 0x40>;
			status = "disabled";
		};

		scif1: serial@c0704000 {
			compatible = "renesas,scif-r8a78000",
				     "renesas,rcar-gen5-scif", "renesas,scif";
			reg = <0 0xc0704000 0 0x40>;
			interrupts = <GIC_ESPI 11 IRQ_TYPE_LEVEL_HIGH>;
			clocks = <&cpg R8A78000_CPG_SGASYNCD16_PERW_BUS>,
				 <&cpg R8A78000_CPG_SGASYNCD4_PERW_BUS>,
				 <&scif_clk>;
			clock-names = "fck", "brg_int", "scif_clk";
			power-domains = <&mdlc_perw R8A78000_MDLC_PD_APL 0x41>;
			resets = <&mdlc_perw 0x41>;
			status = "disabled";
		};

		scif3: serial@c0708000 {
			compatible = "renesas,scif-r8a78000",
				     "renesas,rcar-gen5-scif", "renesas,scif";
			reg = <0 0xc0708000 0 0x40>;
			interrupts = <GIC_ESPI 12 IRQ_TYPE_LEVEL_HIGH>;
			clocks = <&cpg R8A78000_CPG_SGASYNCD16_PERW_BUS>,
				 <&cpg R8A78000_CPG_SGASYNCD4_PERW_BUS>,
				 <&scif_clk>;
			clock-names = "fck", "brg_int", "scif_clk";
			power-domains = <&mdlc_perw R8A78000_MDLC_PD_APL 0x42>;
			resets = <&mdlc_perw 0x42>;
			status = "disabled";
		};

		scif4: serial@c070c000 {
			compatible = "renesas,scif-r8a78000",
				     "renesas,rcar-gen5-scif", "renesas,scif";
			reg = <0 0xc070c000 0 0x40>;
			interrupts = <GIC_ESPI 13 IRQ_TYPE_LEVEL_HIGH>;
			clocks = <&cpg R8A78000_CPG_SGASYNCD16_PERW_BUS>,
				 <&cpg R8A78000_CPG_SGASYNCD4_PERW_BUS>,
				 <&scif_clk>;
			clock-names = "fck", "brg_int", "scif_clk";
			power-domains = <&mdlc_perw R8A78000_MDLC_PD_APL 0x43>;
			resets = <&mdlc_perw 0x43>;
			status = "disabled";
		};

		hscif0: serial@c0710000 {
			compatible = "renesas,hscif-r8a78000",
				     "renesas,rcar-gen5-hscif", "renesas,hscif";
			reg = <0 0xc0710000 0 0x60>;
			interrupts = <GIC_ESPI 14 IRQ_TYPE_LEVEL_HIGH>;
			clocks = <&cpg R8A78000_CPG_SGASYNCD4_PERW_BUS>,
				 <&cpg R8A78000_CPG_SGASYNCD4_PERW_BUS>,
				 <&scif_clk>;
			clock-names = "fck", "brg_int", "scif_clk";
			power-domains = <&mdlc_perw R8A78000_MDLC_PD_APL 0x54>;
			resets = <&mdlc_perw 0x54>;
			status = "disabled";
		};

		hscif1: serial@c0714000 {
			compatible = "renesas,hscif-r8a78000",
				     "renesas,rcar-gen5-hscif", "renesas,hscif";
			reg = <0 0xc0714000 0 0x60>;
			interrupts = <GIC_ESPI 15 IRQ_TYPE_LEVEL_HIGH>;
			clocks = <&cpg R8A78000_CPG_SGASYNCD4_PERW_BUS>,
				 <&cpg R8A78000_CPG_SGASYNCD4_PERW_BUS>,
				 <&scif_clk>;
			clock-names = "fck", "brg_int", "scif_clk";
			power-domains = <&mdlc_perw R8A78000_MDLC_PD_APL 0x55>;
			resets = <&mdlc_perw 0x55>;
			status = "disabled";
		};

		hscif2: serial@c0718000 {
			compatible = "renesas,hscif-r8a78000",
				     "renesas,rcar-gen5-hscif", "renesas,hscif";
			reg = <0 0xc0718000 0 0x60>;
			interrupts = <GIC_ESPI 16 IRQ_TYPE_LEVEL_HIGH>;
			clocks = <&cpg R8A78000_CPG_SGASYNCD4_PERW_BUS>,
				 <&cpg R8A78000_CPG_SGASYNCD4_PERW_BUS>,
				 <&scif_clk>;
			clock-names = "fck", "brg_int", "scif_clk";
			power-domains = <&mdlc_perw R8A78000_MDLC_PD_APL 0x56>;
			resets = <&mdlc_perw 0x56>;
			status = "disabled";
		};

		hscif3: serial@c071c000 {
			compatible = "renesas,hscif-r8a78000",
				     "renesas,rcar-gen5-hscif", "renesas,hscif";
			reg = <0 0xc071c000 0 0x60>;
			interrupts = <GIC_ESPI 17 IRQ_TYPE_LEVEL_HIGH>;
			clocks = <&cpg R8A78000_CPG_SGASYNCD4_PERW_BUS>,
				 <&cpg R8A78000_CPG_SGASYNCD4_PERW_BUS>,
				 <&scif_clk>;
			clock-names = "fck", "brg_int", "scif_clk";
			power-domains = <&mdlc_perw R8A78000_MDLC_PD_APL 0x57>;
			resets = <&mdlc_perw 0x57>;
			status = "disabled";
		};

		stcm_transport: sram@c1060000 {
			compatible = "mmio-sram";
			reg = <0x0 0xc1060000 0x0 0x1c00>;
			#address-cells = <1>;
			#size-cells = <1>;
			ranges = <0 0x0 0xc1060000 0x1c00>;
			/* actual transport nodes must be set per board file */
		};

		cpg: clock-controller@c1320000 {
			compatible = "renesas,r8a78000-cpg";
			reg = <0 0xc1320000 0 0x10000>;
			clocks = <&extal_clk>, <&extalr_clk>;
			clock-names = "extal", "extalr";
			#clock-cells = <1>;
			bootph-all;
		};

		mdlc_vipn: system-controller@c3060000 {
			compatible = "renesas,r8a78000-mdlc";
			reg = <0 0xc3060000 0 0x1000>;
			#power-domain-cells = <2>;
			#reset-cells = <1>;
			bootph-all;
		};

		mdlc_vips: system-controller@c3460000 {
			compatible = "renesas,r8a78000-mdlc";
			reg = <0 0xc3460000 0 0x1000>;
			#power-domain-cells = <2>;
			#reset-cells = <1>;
			bootph-all;
		};

		mdlc_vio: system-controller@c5000000 {
			compatible = "renesas,r8a78000-mdlc";
			reg = <0 0xc5000000 0 0x1000>;
			#power-domain-cells = <2>;
			#reset-cells = <1>;
			bootph-all;
		};

		mdlc_pere: system-controller@c08f0000 {
			compatible = "renesas,r8a78000-mdlc";
			reg = <0 0xc08f0000 0 0x1000>;
			#power-domain-cells = <2>;
			#reset-cells = <1>;
			bootph-all;
		};

		mdlc_perw: system-controller@c05d0000 {
			compatible = "renesas,r8a78000-mdlc";
			reg = <0 0xc05d0000 0 0x1000>;
			#power-domain-cells = <2>;
			#reset-cells = <1>;
			bootph-all;
		};

		mdlc_ddr0: system-controller@e8000000 {
			compatible = "renesas,r8a78000-mdlc";
			reg = <0 0xe8000000 0 0x1000>;
			#power-domain-cells = <2>;
			#reset-cells = <1>;
			bootph-all;
		};

		mdlc_ddr1: system-controller@e8080000 {
			compatible = "renesas,r8a78000-mdlc";
			reg = <0 0xe8080000 0 0x1000>;
			#power-domain-cells = <2>;
			#reset-cells = <1>;
			bootph-all;
		};

		mdlc_ddr2: system-controller@e8100000 {
			compatible = "renesas,r8a78000-mdlc";
			reg = <0 0xe8100000 0 0x1000>;
			#power-domain-cells = <2>;
			#reset-cells = <1>;
			bootph-all;
		};

		mdlc_ddr3: system-controller@e8180000 {
			compatible = "renesas,r8a78000-mdlc";
			reg = <0 0xe8180000 0 0x1000>;
			#power-domain-cells = <2>;
			#reset-cells = <1>;
			bootph-all;
		};

		mdlc_ddr4: system-controller@e8200000 {
			compatible = "renesas,r8a78000-mdlc";
			reg = <0 0xe8200000 0 0x1000>;
			#power-domain-cells = <2>;
			#reset-cells = <1>;
			bootph-all;
		};

		mdlc_ddr5: system-controller@e8280000 {
			compatible = "renesas,r8a78000-mdlc";
			reg = <0 0xe8280000 0 0x1000>;
			#power-domain-cells = <2>;
			#reset-cells = <1>;
			bootph-all;
		};

		mdlc_ddr6: system-controller@e8300000 {
			compatible = "renesas,r8a78000-mdlc";
			reg = <0 0xe8300000 0 0x1000>;
			#power-domain-cells = <2>;
			#reset-cells = <1>;
			bootph-all;
		};

		mdlc_ddr7: system-controller@e8380000 {
			compatible = "renesas,r8a78000-mdlc";
			reg = <0 0xe8380000 0 0x1000>;
			#power-domain-cells = <2>;
			#reset-cells = <1>;
			bootph-all;
		};

		mdlc_hscn: system-controller@c9c90000 {
			compatible = "renesas,r8a78000-mdlc";
			reg = <0 0xc9c90000 0 0x1000>;
			#power-domain-cells = <2>;
			#reset-cells = <1>;
			bootph-all;
		};

		mdlc_rt: system-controller@19440000 {
			compatible = "renesas,r8a78000-mdlc";
			reg = <0 0x19440000 0 0x1000>;
			#power-domain-cells = <2>;
			#reset-cells = <1>;
			bootph-all;
		};

		mdlc_top: system-controller@c6480000 {
			compatible = "renesas,r8a78000-mdlc";
			reg = <0 0xc6480000 0 0x1000>;
			#power-domain-cells = <2>;
			#reset-cells = <1>;
			bootph-all;
		};

		mdlc_hscs: system-controller@de200000 {
			compatible = "renesas,r8a78000-mdlc";
			reg = <0 0xde200000 0 0x1000>;
			#power-domain-cells = <2>;
			#reset-cells = <1>;
			bootph-all;
		};

		mdlc_imn: system-controller@c1990000 {
			compatible = "renesas,r8a78000-mdlc";
			reg = <0 0xc1990000 0 0x1000>;
			#power-domain-cells = <2>;
			#reset-cells = <1>;
			bootph-all;
		};

		mdlc_ims: system-controller@c1d90000 {
			compatible = "renesas,r8a78000-mdlc";
			reg = <0 0xc1d90000 0 0x1000>;
			#power-domain-cells = <2>;
			#reset-cells = <1>;
			bootph-all;
		};

		mdlc_gpc: system-controller@cb510000 {
			compatible = "renesas,r8a78000-mdlc";
			reg = <0 0xcb510000 0 0x1000>;
			#power-domain-cells = <2>;
			#reset-cells = <1>;
			bootph-all;
		};

		mdlc_dsp: system-controller@cbe90000 {
			compatible = "renesas,r8a78000-mdlc";
			reg = <0 0xcbe90000 0 0x1000>;
			#power-domain-cells = <2>;
			#reset-cells = <1>;
			bootph-all;
		};

		mdlc_mm: system-controller@e9980000 {
			compatible = "renesas,r8a78000-mdlc";
			reg = <0 0xe9980000 0 0x1000>;
			#power-domain-cells = <2>;
			#reset-cells = <1>;
			bootph-all;
		};

		mdlc_npu0: system-controller@d2c30000 {
			compatible = "renesas,r8a78000-mdlc";
			reg = <0 0xd2c30000 0 0x1000>;
			#power-domain-cells = <2>;
			#reset-cells = <1>;
			bootph-all;
		};

		mdlc_npu1: system-controller@d6c30000 {
			compatible = "renesas,r8a78000-mdlc";
			reg = <0 0xd6c30000 0 0x1000>;
			#power-domain-cells = <2>;
			#reset-cells = <1>;
			bootph-all;
		};

		mdlc_cmnn: system-controller@ca410000 {
			compatible = "renesas,r8a78000-mdlc";
			reg = <0 0xca410000 0 0x1000>;
			#power-domain-cells = <2>;
			#reset-cells = <1>;
			bootph-all;
		};

		mdlc_cmns: system-controller@ca510000 {
			compatible = "renesas,r8a78000-mdlc";
			reg = <0 0xca510000 0 0x1000>;
			#power-domain-cells = <2>;
			#reset-cells = <1>;
			bootph-all;
		};

		mdlc_scp: system-controller@c1330000 {
			compatible = "renesas,r8a78000-mdlc";
			reg = <0 0xc1330000 0 0x1000>;
			#power-domain-cells = <2>;
			#reset-cells = <1>;
			bootph-all;
		};

		mdlc_aon: system-controller@c1338000 {
			compatible = "renesas,r8a78000-mdlc";
			reg = <0 0xc1338000 0 0x1000>;
			#power-domain-cells = <2>;
			#reset-cells = <1>;
			bootph-all;
		};

		ufs1: ufs@c0a40000 { // FIXME
			compatible = "renesas,r8a78000-ufs";
			reg = <0 0xc0a40000 0 0x100>, <0 0xc0a00000 0 0x40000>;
			interrupts = <GIC_ESPI 220 IRQ_TYPE_LEVEL_HIGH>;
			clocks = <&cpg R8A78000_CPG_S0D4_PERE_MAIN>,
				 <&ufs1_ref_clk>;
			clock-names = "fck", "ref_clk";
			power-domains = <&mdlc_pere 0x01 0x61>;
			resets = <&mdlc_pere 0x61>;
			status = "disabled";
		};

		mp_phy: mp_phy@c9a00000 {
			compatible = "renesas,r8a78000-mpphy",
				     "renesas,rcar-gen5-mpphy";
			reg = <0 0xc9a00000 0 0x100000>;
			#phy-cells = <2>;
			power-domains = <&scmi_devpd 17>, /* R8A78000_SCMI_PD_MPP0 */
					<&scmi_devpd 18>, /* R8A78000_SCMI_PD_MPP1 */
					<&scmi_devpd 19>, /* R8A78000_SCMI_PD_MPP2 */
					<&scmi_devpd 20>; /* R8A78000_SCMI_PD_MPP3 */
			power-domain-names = "mpp0", "mpp1", "mpp2", "mpp3";
			clocks = <&scmi_clk 340>, /* R8A78000_SCMI_CLOCK_MDLC_MPPHY01 */
				 <&scmi_clk 341>, /* R8A78000_SCMI_CLOCK_MDLC_MPPHY11 */
				 <&scmi_clk 342>, /* R8A78000_SCMI_CLOCK_MDLC_MPPHY21 */
				 <&scmi_clk 343>, /* R8A78000_SCMI_CLOCK_MDLC_MPPHY31 */
				 <&scmi_clk 344>; /* R8A78000_SCMI_CLOCK_MDLC_MPPHY02 */
			clock-names = "mpphy01", "mpphy11", "mpphy21", "mpphy31", "mpphy02";
			resets = <&scmi_reset 340>, /* R8A78000_SCMI_RESET_MPPHY01 */
				 <&scmi_reset 341>, /* R8A78000_SCMI_RESET_MPPHY11 */
				 <&scmi_reset 342>, /* R8A78000_SCMI_RESET_MPPHY21 */
				 <&scmi_reset 343>, /* R8A78000_SCMI_RESET_MPPHY31 */
				 <&scmi_reset 344>; /* R8A78000_SCMI_RESET_MPPHY02 */
			reset-names = "mpphy01", "mpphy11", "mpphy21", "mpphy31", "mpphy02";
			status = "disabled";
		};

		pciec40: pcie@c9000000 {
			compatible = "renesas,r8a78000-pcie4",
				     "renesas,rcar-gen5-pcie4";
			reg = <0 0xc9000000 0 0x2000>, <0 0xc9002000 0 0x1000>,
			      <0 0xc9003000 0 0x2000>, <0 0xc9005000 0 0x1000>,
			      <0 0xc9c8e200 0 0xe00>, <1 0x00000000 0 0x10000000>;
			reg-names = "dbi", "dbi2", "atu", "dma", "app", "config";
			interrupts = <GIC_ESPI 236 IRQ_TYPE_LEVEL_HIGH>,
				     <GIC_ESPI 227 IRQ_TYPE_LEVEL_HIGH>,
				     <GIC_ESPI 228 IRQ_TYPE_LEVEL_HIGH>,
				     <GIC_ESPI 229 IRQ_TYPE_LEVEL_HIGH>;
			interrupt-names = "msi", "dma", "sft_ce", "app";
			clocks = <&scmi_clk 345>, <&pcie40_clkref>; /* R8A78000_SCMI_CLOCK_MDLC_PCI401 */
			clock-names = "core", "ref";
			power-domains = <&scmi_devpd 14>; /* R8A78000_SCMI_PD_PCI4 */
			resets = <&scmi_reset 345>; /* R8A78000_SCMI_RESET_PCI401 */
			reset-names = "pwr";
			max-link-speed = <4>;
			num-lanes = <2>;
			#address-cells = <3>;
			#size-cells = <2>;
			bus-range = <0x00 0xff>;
			device_type = "pci";
			phys = <&mp_phy 0 1>;
			/*
			 * The "ranges" here work according to IEEE Std 1275-1994:
			 *
			 *     0x03000000 - 64-bit-address Memory Space
			 *   0 0x10000000 - 64-bit-address in PCIe address space
			 *
			 *   1 0x10000000 - 64-bit-address in SoC address space
			 *
			 *   0 0x10000000 - mapping size is 256 MiB
			 *
			 * This describes 256 MiB long 64-bit-address mapping
			 * between PCIe address range 0x1000_0000..0x1fff_ffff
			 * and SoC address range 0x1_1000_0000..0x1_1fff_ffff .
			 *
			 * However, the PCIe window on this SoC is 512 MiB
			 * long. The first part of the mapping is described in
			 * the "reg" property entry labeled as "config", which
			 * describes PCIe config space at address range
			 * 0x1_0000_0000..0x1_0fff_ffff .
			 */
			ranges = <0x03000000 0 0x10000000 1 0x10000000 0 0x10000000>;
			dma-ranges = <0x43000000 0 0x00000000 0 0x00000000 0x100 0x00000000>;
			#interrupt-cells = <1>;
			interrupt-map-mask = <0 0 0 7>;
			interrupt-map = <0 0 0 1 &gic GIC_ESPI 236 IRQ_TYPE_LEVEL_HIGH
					 0 0 0 2 &gic GIC_ESPI 236 IRQ_TYPE_LEVEL_HIGH
					 0 0 0 3 &gic GIC_ESPI 236 IRQ_TYPE_LEVEL_HIGH
					 0 0 0 4 &gic GIC_ESPI 236 IRQ_TYPE_LEVEL_HIGH>;
			snps,enable-cdm-check;
			status = "disabled";

			/* PCIe bridge, Root Port */
			pciec40_rp: pci@0,0 {
				#address-cells = <3>;
				#size-cells = <2>;
				reg = <0x0 0x0 0x0 0x0 0x0>;
				compatible = "pciclass,0604";
				device_type = "pci";
				ranges;
			};
		};

		pciec41: pcie@c9400000 {
			compatible = "renesas,r8a78000-pcie4",
				     "renesas,rcar-gen5-pcie4";
			reg = <0 0xc9400000 0 0x2000>, <0 0xc9402000 0 0x1000>,
			      <0 0xc9403000 0 0x2000>, <0 0xc9405000 0 0x1000>,
			      <0 0xc9c8f200 0 0xe00>, <1 0x20000000 0 0x10000000>;
			reg-names = "dbi", "dbi2", "atu", "dma", "app", "config";
			interrupts = <GIC_ESPI 240 IRQ_TYPE_LEVEL_HIGH>,
				     <GIC_ESPI 230 IRQ_TYPE_LEVEL_HIGH>,
				     <GIC_ESPI 231 IRQ_TYPE_LEVEL_HIGH>,
				     <GIC_ESPI 232 IRQ_TYPE_LEVEL_HIGH>;
			interrupt-names = "msi", "dma", "sft_ce", "app";
			clocks = <&scmi_clk 346>, <&pcie41_clkref>; /* R8A78000_SCMI_CLOCK_MDLC_PCI411 */
			clock-names = "core", "ref";
			power-domains = <&scmi_devpd 14>; /* R8A78000_SCMI_PD_PCI4 */
			phys = <&mp_phy 1 1>;
			resets = <&scmi_reset 346>; /* R8A78000_SCMI_RESET_PCI411 */
			reset-names = "pwr";
			max-link-speed = <4>;
			num-lanes = <2>;
			#address-cells = <3>;
			#size-cells = <2>;
			bus-range = <0x00 0xff>;
			device_type = "pci";
			/*
			 * The "ranges" here work according to IEEE Std 1275-1994:
			 *
			 *     0x03000000 - 64-bit-address Memory Space
			 *   0 0x30000000 - 64-bit-address in PCIe address space
			 *
			 *   1 0x30000000 - 64-bit-address in SoC address space
			 *
			 *   0 0x10000000 - mapping size is 256 MiB
			 *
			 * This describes 256 MiB long 64-bit-address mapping
			 * between PCIe address range 0x3000_0000..0x3fff_ffff
			 * and SoC address range 0x1_3000_0000..0x1_3fff_ffff .
			 *
			 * However, the PCIe window on this SoC is 512 MiB
			 * long. The first part of the mapping is described in
			 * the "reg" property entry labeled as "config", which
			 * describes PCIe config space at address range
			 * 0x1_2000_0000..0x1_2fff_ffff .
			 */
			ranges = <0x03000000 0 0x30000000 1 0x30000000 0 0x10000000>;
			dma-ranges = <0x43000000 0 0x00000000 0 0x00000000 0x100 0x00000000>;
			#interrupt-cells = <1>;
			interrupt-map-mask = <0 0 0 7>;
			interrupt-map = <0 0 0 1 &gic GIC_ESPI 240 IRQ_TYPE_LEVEL_HIGH
					 0 0 0 2 &gic GIC_ESPI 240 IRQ_TYPE_LEVEL_HIGH
					 0 0 0 3 &gic GIC_ESPI 240 IRQ_TYPE_LEVEL_HIGH
					 0 0 0 4 &gic GIC_ESPI 240 IRQ_TYPE_LEVEL_HIGH>;
			snps,enable-cdm-check;
			status = "disabled";

			/* PCIe bridge, Root Port */
			pciec41_rp: pci@0,0 {
				#address-cells = <3>;
				#size-cells = <2>;
				reg = <0x0 0x0 0x0 0x0 0x0>;
				compatible = "pciclass,0604";
				device_type = "pci";
				ranges;
			};
		};

		/* Test bindings */
		usb20: usb@c9c56000 {
			compatible = "renesas,rcar-gen5-usb";
			reg = <0 0xc9c56000 0 0x2000>;
			phy-names = "usb2-phy";
			#address-cells = <2>;
			#size-cells = <2>;
			/* CRITICAL FIX: Proper address translation */
			ranges = <0x0 0xc8900000 0x0 0xc8900000 0x0 0x100000>;
			power-domains = <&scmi_devpd 16>; /* R8A78000_SCMI_PD_USB */
			clocks = <&scmi_clk 337>; /* R8A78000_SCMI_CLOCK_MDLC_US31 */
			clock-names = "usb20";
			resets = <&scmi_reset 337>; /* R8A78000_SCMI_RESET_US31 */
			reset-names = "usb20";
			status = "disabled";
		};

		usb21: usb@c9c5a000 {
			compatible = "renesas,rcar-gen5-usb";
			reg = <0 0xc9c5a000 0 0x2000>;
			phy-names = "usb2-phy";
			#address-cells = <2>;
			#size-cells = <2>;
			/* CRITICAL FIX: Proper address translation */
			ranges = <0x0 0xc8b00000 0x0 0xc8b00000 0x0 0x100000>;
			power-domains = <&scmi_devpd 16>; /* R8A78000_SCMI_PD_USB */
			clocks = <&scmi_clk 339>; /* R8A78000_SCMI_CLOCK_MDLC_US33 */
			clock-names = "usb21";
			resets = <&scmi_reset 339>; /* R8A78000_SCMI_RESET_US33 */
			reset-names = "usb21";
			status = "disabled";
		};

		usb30: usb@c9c54000 {
			compatible = "renesas,rcar-gen5-usb";
			reg = <0 0xc9c54000 0 0x2000>;
			#address-cells = <2>;
			#size-cells = <2>;
			/* CRITICAL FIX: Proper address translation */
			ranges = <0x0 0xc8800000 0x0 0xc8800000 0x0 0x100000>;
			power-domains = <&scmi_devpd 16>; /* R8A78000_SCMI_PD_USB */
			clocks = <&scmi_clk 336>; /* R8A78000_SCMI_CLOCK_MDLC_US30 */
			clock-names = "usb30";
			resets = <&scmi_reset 336>; /* R8A78000_SCMI_RESET_US30 */
			reset-names = "usb30";
			status = "disabled";
		};

		usb31: usb@c9c58000 {
			compatible = "renesas,rcar-gen5-usb";
			reg = <0 0xc9c58000 0 0x2000>;
			#address-cells = <2>;
			#size-cells = <2>;
			/* CRITICAL FIX: Proper address translation */
			ranges = <0x0 0xc8a00000 0x0 0xc8a00000 0x0 0x100000>;
			power-domains = <&scmi_devpd 16>; /* R8A78000_SCMI_PD_USB */
			clocks = <&scmi_clk 338>; /* R8A78000_SCMI_CLOCK_MDLC_US32 */
			clock-names = "usb31";
			resets = <&scmi_reset 338>; /* R8A78000_SCMI_RESET_US32 */
			reset-names = "usb31";
			status = "disabled";
		};

		rswitch3: ethernet@c9bc0000 {
			compatible = "renesas,r8a78000-ether-switch";
			reg = <0 0xc9bc0000 0 0x0040000>,  // base
			      <0 0xc9b80000 0 0x00040000>, // secure_base
			      <0 0xc9c88000 0x0 0x800>,
			      <0 0xc9c89000 0 0x800>;
			reg-names = "base", "secure_base",
				    "gptp_base", "secure_ptp";
			interrupts = <GIC_SPI 799 IRQ_TYPE_LEVEL_HIGH>,
				 <GIC_SPI 800 IRQ_TYPE_LEVEL_HIGH>,
				 <GIC_SPI 801 IRQ_TYPE_LEVEL_HIGH>,
				 <GIC_SPI 802 IRQ_TYPE_LEVEL_HIGH>,
				 <GIC_SPI 803 IRQ_TYPE_LEVEL_HIGH>,
				 <GIC_SPI 804 IRQ_TYPE_LEVEL_HIGH>,
				 <GIC_SPI 805 IRQ_TYPE_LEVEL_HIGH>,
				 <GIC_SPI 806 IRQ_TYPE_LEVEL_HIGH>,
				 <GIC_SPI 807 IRQ_TYPE_LEVEL_HIGH>,
				 <GIC_SPI 808 IRQ_TYPE_LEVEL_HIGH>,
				 <GIC_SPI 809 IRQ_TYPE_LEVEL_HIGH>,
				 <GIC_SPI 810 IRQ_TYPE_LEVEL_HIGH>,
				 <GIC_SPI 811 IRQ_TYPE_LEVEL_HIGH>,
				 <GIC_SPI 812 IRQ_TYPE_LEVEL_HIGH>,
				 <GIC_SPI 813 IRQ_TYPE_LEVEL_HIGH>,
				 <GIC_SPI 814 IRQ_TYPE_LEVEL_HIGH>,
				 <GIC_SPI 815 IRQ_TYPE_LEVEL_HIGH>,
				 <GIC_SPI 816 IRQ_TYPE_LEVEL_HIGH>,
				 <GIC_SPI 817 IRQ_TYPE_LEVEL_HIGH>,
				 <GIC_SPI 818 IRQ_TYPE_LEVEL_HIGH>,
				 <GIC_SPI 819 IRQ_TYPE_LEVEL_HIGH>,
				 <GIC_SPI 820 IRQ_TYPE_LEVEL_HIGH>,
				 <GIC_SPI 821 IRQ_TYPE_LEVEL_HIGH>,
				 <GIC_SPI 822 IRQ_TYPE_LEVEL_HIGH>,
				 <GIC_SPI 823 IRQ_TYPE_LEVEL_HIGH>,
				 <GIC_SPI 824 IRQ_TYPE_LEVEL_HIGH>,
				 <GIC_SPI 825 IRQ_TYPE_LEVEL_HIGH>,
				 <GIC_SPI 826 IRQ_TYPE_LEVEL_HIGH>,
				 <GIC_SPI 827 IRQ_TYPE_LEVEL_HIGH>,
				 <GIC_SPI 828 IRQ_TYPE_LEVEL_HIGH>,
				 <GIC_SPI 829 IRQ_TYPE_LEVEL_HIGH>,
				 <GIC_SPI 830 IRQ_TYPE_LEVEL_HIGH>,
				 <GIC_SPI 831 IRQ_TYPE_LEVEL_HIGH>,
				 <GIC_SPI 832 IRQ_TYPE_LEVEL_HIGH>,
				 <GIC_SPI 833 IRQ_TYPE_LEVEL_HIGH>,
				 <GIC_SPI 834 IRQ_TYPE_LEVEL_HIGH>,
				 <GIC_SPI 835 IRQ_TYPE_LEVEL_HIGH>,
				 <GIC_SPI 836 IRQ_TYPE_LEVEL_HIGH>,
				 <GIC_SPI 837 IRQ_TYPE_LEVEL_HIGH>,
				 <GIC_SPI 838 IRQ_TYPE_LEVEL_HIGH>,
				 <GIC_SPI 839 IRQ_TYPE_LEVEL_HIGH>,
				 <GIC_SPI 840 IRQ_TYPE_LEVEL_HIGH>,
				 <GIC_SPI 841 IRQ_TYPE_LEVEL_HIGH>,
				 <GIC_SPI 842 IRQ_TYPE_LEVEL_HIGH>,
				 <GIC_SPI 843 IRQ_TYPE_LEVEL_HIGH>,
				 <GIC_SPI 844 IRQ_TYPE_LEVEL_HIGH>,
				 <GIC_SPI 845 IRQ_TYPE_LEVEL_HIGH>,
				 <GIC_SPI 846 IRQ_TYPE_LEVEL_HIGH>,
				 <GIC_SPI 847 IRQ_TYPE_LEVEL_HIGH>,
				 <GIC_SPI 848 IRQ_TYPE_LEVEL_HIGH>,
				 <GIC_SPI 849 IRQ_TYPE_LEVEL_HIGH>,
				 <GIC_SPI 850 IRQ_TYPE_LEVEL_HIGH>,
				 <GIC_SPI 851 IRQ_TYPE_LEVEL_HIGH>,
				 <GIC_SPI 852 IRQ_TYPE_LEVEL_HIGH>,
				 <GIC_SPI 853 IRQ_TYPE_LEVEL_HIGH>,
				 <GIC_SPI 854 IRQ_TYPE_LEVEL_HIGH>,
				 <GIC_SPI 855 IRQ_TYPE_LEVEL_HIGH>,
				 <GIC_SPI 856 IRQ_TYPE_LEVEL_HIGH>,
				 <GIC_SPI 857 IRQ_TYPE_LEVEL_HIGH>,
				 <GIC_SPI 858 IRQ_TYPE_LEVEL_HIGH>,
				 <GIC_SPI 859 IRQ_TYPE_LEVEL_HIGH>,
				 <GIC_SPI 860 IRQ_TYPE_LEVEL_HIGH>,
				 <GIC_SPI 861 IRQ_TYPE_LEVEL_HIGH>,
				 <GIC_SPI 862 IRQ_TYPE_LEVEL_HIGH>,
				 <GIC_SPI 863 IRQ_TYPE_LEVEL_HIGH>,
				 <GIC_SPI 864 IRQ_TYPE_LEVEL_HIGH>,
				 <GIC_SPI 865 IRQ_TYPE_LEVEL_HIGH>,
				 <GIC_SPI 866 IRQ_TYPE_LEVEL_HIGH>,
				 <GIC_SPI 867 IRQ_TYPE_LEVEL_HIGH>,
				 <GIC_SPI 868 IRQ_TYPE_LEVEL_HIGH>,
				 <GIC_SPI 869 IRQ_TYPE_LEVEL_HIGH>,
				 <GIC_SPI 870 IRQ_TYPE_LEVEL_HIGH>,
				 <GIC_SPI 871 IRQ_TYPE_LEVEL_HIGH>,
				 <GIC_SPI 872 IRQ_TYPE_LEVEL_HIGH>,
				 <GIC_SPI 873 IRQ_TYPE_LEVEL_HIGH>,
				 <GIC_SPI 874 IRQ_TYPE_LEVEL_HIGH>,
				 <GIC_SPI 875 IRQ_TYPE_LEVEL_HIGH>,
				 <GIC_SPI 876 IRQ_TYPE_LEVEL_HIGH>,
				 <GIC_SPI 877 IRQ_TYPE_LEVEL_HIGH>,
				 <GIC_SPI 878 IRQ_TYPE_LEVEL_HIGH>,
				 <GIC_SPI 879 IRQ_TYPE_LEVEL_HIGH>,
				 <GIC_SPI 880 IRQ_TYPE_LEVEL_HIGH>,
				 <GIC_SPI 881 IRQ_TYPE_LEVEL_HIGH>,
				 <GIC_SPI 882 IRQ_TYPE_LEVEL_HIGH>,
				 <GIC_SPI 883 IRQ_TYPE_LEVEL_HIGH>,
				 <GIC_SPI 884 IRQ_TYPE_LEVEL_HIGH>,
				 <GIC_SPI 885 IRQ_TYPE_LEVEL_HIGH>,
				 <GIC_SPI 886 IRQ_TYPE_LEVEL_HIGH>,
				 <GIC_SPI 887 IRQ_TYPE_LEVEL_HIGH>,
				 <GIC_SPI 888 IRQ_TYPE_LEVEL_HIGH>,
				 <GIC_SPI 889 IRQ_TYPE_LEVEL_HIGH>,
				 <GIC_SPI 890 IRQ_TYPE_LEVEL_HIGH>,
				 <GIC_SPI 891 IRQ_TYPE_LEVEL_HIGH>;
			interrupt-names =
				"race_wrap_mfwd_int", "race_wrap_race_int",
				"race_wrap_coma_int", "race_wrap_gwca0_int",
				"race_wrap_gwca1_int", "race_wrap_etha0_int",
				"race_wrap_etha1_int", "race_wrap_etha2_int",
				"race_wrap_etha3_int", "race_wrap_etha4_int",
				"race_wrap_etha5_int", "race_wrap_etha6_int",
				"race_wrap_etha7_int", "race_wrap_etha8_int",
				"race_wrap_etha9_int", "race_wrap_etha10_int",
				"race_wrap_etha11_int", "race_wrap_etha12_int",
				"race_wrap_gwca0_gwdis_int0", "race_wrap_gwca0_gwdis_int1",
				"race_wrap_gwca0_gwdis_int2", "race_wrap_gwca0_gwdis_int3",
				"race_wrap_gwca0_gwdis_int4", "race_wrap_gwca0_gwdis_int5",
				"race_wrap_gwca0_gwdis_int6", "race_wrap_gwca0_gwdis_int7",
				"gwca1_gwdis0", "gwca1_gwdis1", "gwca1_gwdis2", "gwca1_gwdis3",
				"gwca1_gwdis4", "gwca1_gwdis5", "gwca1_gwdis6", "gwca1_gwdis7",
				"race_wrap_gwca0_gwtsdis_int0", "race_wrap_gwca0_gwtsdis_int1",
				"race_wrap_gwca1_gwtsdis_int0", "race_wrap_gwca1_gwtsdis_int1",
				"race_wrap_gptp_int",
				"tes0_status_int", "tes0_tx_int", "tes0_rx_int", "tes0_ts_int",
				"tes0_error_int", "tes1_status_int", "tes1_tx_int",
				"tes1_rx_int", "tes1_ts_int", "tes1_error_int",
				"tes2_status_int", "tes2_tx_int", "tes2_rx_int",
				"tes2_ts_int", "tes2_error_int", "tes3_status_int",
				"tes3_tx_int", "tes3_rx_int", "tes3_ts_int", "tes3_error_int",
				"tes4_status_int", "tes4_tx_int", "tes4_rx_int", "tes4_ts_int",
				"tes4_error_int", "tes5_status_int", "tes5_tx_int",
				"tes5_rx_int", "tes5_ts_int", "tes5_error_int",
				"tes6_status_int", "tes6_tx_int", "tes6_rx_int",
				"tes6_ts_int", "tes6_error_int", "tes7_status_int",
				"tes7_tx_int", "tes7_rx_int", "tes7_ts_int", "tes7_error_int",
				"tes0_gptp_int", "tes1_gptp_int", "tes2_gptp_int",
				"tes3_gptp_int", "tes4_gptp_int", "tes5_gptp_int",
				"tes6_gptp_int", "tes7_gptp_int",
				"race_wrap_msc0_error_int", "race_wrap_msc1_error_int",
				"race_wrap_msc2_error_int", "race_wrap_msc3_error_int",
				"race_wrap_msc4_error_int", "race_wrap_msc5_error_int",
				"race_wrap_msc6_error_int", "race_wrap_msc7_error_int";

			power-domains = <&scmi_devpd 15>; /* R8A78000_SCMI_PD_RSW */
			clocks = <&scmi_clk 320>, /* R8A78000_SCMI_CLOCK_MDLC_RSW3 */
				 <&scmi_clk 321>, /* R8A78000_SCMI_CLOCK_MDLC_RSW3TSN */
				 <&scmi_clk 322>, /* R8A78000_SCMI_CLOCK_MDLC_RSW3AES */
				 <&scmi_clk 323>, /* R8A78000_SCMI_CLOCK_MDLC_RSW3TSNTES0 */
				 <&scmi_clk 324>, /* R8A78000_SCMI_CLOCK_MDLC_RSW3TSNTES1 */
				 <&scmi_clk 325>, /* R8A78000_SCMI_CLOCK_MDLC_RSW3TSNTES2 */
				 <&scmi_clk 326>, /* R8A78000_SCMI_CLOCK_MDLC_RSW3TSNTES3 */
				 <&scmi_clk 327>, /* R8A78000_SCMI_CLOCK_MDLC_RSW3TSNTES4 */
				 <&scmi_clk 328>, /* R8A78000_SCMI_CLOCK_MDLC_RSW3TSNTES5 */
				 <&scmi_clk 329>, /* R8A78000_SCMI_CLOCK_MDLC_RSW3TSNTES6 */
				 <&scmi_clk 330>, /* R8A78000_SCMI_CLOCK_MDLC_RSW3TSNTES7 */
				 <&scmi_clk 331>; /* R8A78000_SCMI_CLOCK_MDLC_RSW3MFWD */
			clock-names = "rsw3", "rsw3tsn", "rsw3aes",
				      "rsw3tsntes0", "rsw3tsntes1", "rsw3tsntes2",
				      "rsw3tsntes3", "rsw3tsntes4", "rsw3tsntes5",
				      "rsw3tsntes6", "rsw3tsntes7", "rsw3mfwd";
			// TODO: Add reset reference if needed
			// resets = <&cpg RSW3_RST>;

			status = "disabled";
		};

		eth_pcs: phy@c9c50000 {
			compatible = "renesas,r8a78000-ether-pcs";
			reg = <0 0xc9c50000 0 0x4000>;
			#phy-cells = <1>;
			power-domains = <&scmi_devpd 19>; /* R8A78000_SCMI_PD_MPP2 */
			clocks = <&scmi_clk 312>, /* R8A78000_SCMI_CLOCK_MDLC_XPCS0 */
				 <&scmi_clk 313>, /* R8A78000_SCMI_CLOCK_MDLC_XPCS1 */
				 <&scmi_clk 314>, /* R8A78000_SCMI_CLOCK_MDLC_XPCS2 */
				 <&scmi_clk 315>, /* R8A78000_SCMI_CLOCK_MDLC_XPCS3 */
				 <&scmi_clk 316>, /* R8A78000_SCMI_CLOCK_MDLC_XPCS4 */
				 <&scmi_clk 317>, /* R8A78000_SCMI_CLOCK_MDLC_XPCS5 */
				 <&scmi_clk 318>, /* R8A78000_SCMI_CLOCK_MDLC_XPCS6 */
				 <&scmi_clk 319>; /* R8A78000_SCMI_CLOCK_MDLC_XPCS7 */
			clock-names = "xpcs0", "xpcs1", "xpcs2", "xpcs3",
				      "xpcs4", "xpcs5", "xpcs6", "xpcs7";
			resets = <&scmi_reset 312>, /* R8A78000_SCMI_RESET_XPCS0 */
				 <&scmi_reset 313>, /* R8A78000_SCMI_RESET_XPCS1 */
				 <&scmi_reset 314>, /* R8A78000_SCMI_RESET_XPCS2 */
				 <&scmi_reset 315>, /* R8A78000_SCMI_RESET_XPCS3 */
				 <&scmi_reset 316>, /* R8A78000_SCMI_RESET_XPCS4 */
				 <&scmi_reset 317>, /* R8A78000_SCMI_RESET_XPCS5 */
				 <&scmi_reset 318>, /* R8A78000_SCMI_RESET_XPCS6 */
				 <&scmi_reset 319>; /* R8A78000_SCMI_RESET_XPCS7 */
			reset-names = "pcs0", "pcs1", "pcs2", "pcs3",
				      "pcs4", "pcs5", "pcs6", "pcs7";
			status = "disabled";
		};

		tsnes3: ethernet@c9c6c000 {
			compatible = "renesas,r8a78000-ethertsn";
			reg = <0 0xc9c6c000 0 0x4000>,
				  <0 0xc9ca3000 0 0x800>;
			reg-names = "tsnes", "gptp";
			interrupts = <GIC_SPI 853 IRQ_TYPE_LEVEL_HIGH>,
					<GIC_SPI 854 IRQ_TYPE_LEVEL_HIGH>,
					<GIC_SPI 855 IRQ_TYPE_LEVEL_HIGH>,
					<GIC_SPI 856 IRQ_TYPE_LEVEL_HIGH>,
					<GIC_SPI 857 IRQ_TYPE_LEVEL_HIGH>;
			interrupt-names = "status", "tx", "rx", "ts", "error";
			power-domains = <&scmi_devpd 15>; /* R8A78000_SCMI_PD_RSW */
			clocks = <&scmi_clk 321>, /* R8A78000_SCMI_CLOCK_MDLC_RSW3TSN */
				 <&scmi_clk 326>; /* R8A78000_SCMI_CLOCK_MDLC_RSW3TSNTES3 */
			clock-names = "rsw3tsn", "tsnes";
			renesas,gptp-domain = "a";
			phy-mode = "gmii";
			max-speed = <2500>;
			renesas,tsnes-id = <3>;
			renesas,rswitch = <&rswitch3>;
			renesas,rswitch-if = <8>;
			renesas,rswitch-forward-ports = <4>;
			status = "disabled";
			fixed-link {
				speed = <2500>;
				full-duplex;
			};
		};
	};

	timer {
		compatible = "arm,armv8-timer";
		interrupts = <GIC_PPI 13 IRQ_TYPE_LEVEL_LOW>,
			     <GIC_PPI 14 IRQ_TYPE_LEVEL_LOW>,
			     <GIC_PPI 11 IRQ_TYPE_LEVEL_LOW>,
			     <GIC_PPI 10 IRQ_TYPE_LEVEL_LOW>,
			     <GIC_PPI 12 IRQ_TYPE_LEVEL_LOW>;
		interrupt-names = "sec-phys", "phys", "virt", "hyp-phys", "hyp-virt";
	};

	ufs1_ref_clk: ufs1-ref-clk {
		compatible = "fixed-clock";
		#clock-cells = <0>;
		/* This value must be overridden by the board */
		clock-frequency = <0>;
	};
};
